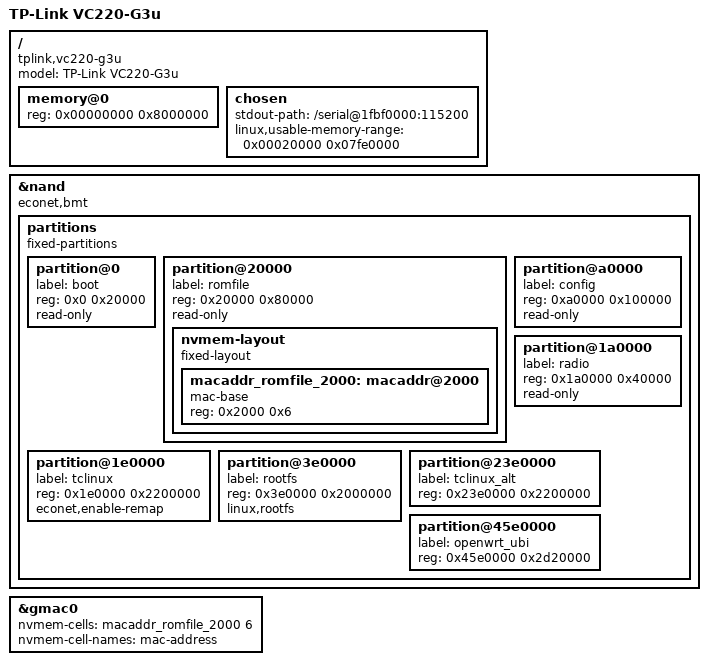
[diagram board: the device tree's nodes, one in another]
// SPDX-License-Identifier: (GPL-2.0-only OR BSD-2-Clause)
/dts-v1/;

#include "en751221.dtsi"

/ {
	model = "TP-Link VC220-G3u";
	compatible = "tplink,vc220-g3u", "econet,en751221";

	memory@0 {
		device_type = "memory";
		reg = <0x00000000 0x8000000>;
	};

	chosen {
		stdout-path = "/serial@1fbf0000:115200";
		linux,usable-memory-range = <0x00020000 0x07fe0000>;
	};
};

&nand {
	status = "okay";
	econet,bmt;

	partitions {
		compatible = "fixed-partitions";
		#address-cells = <1>;
		#size-cells = <1>;

		partition@0 {
			label = "boot";
			reg = <0x0 0x20000>;
			read-only;
		};
		partition@20000 {
			label = "romfile";
			reg = <0x20000 0x80000>;
			read-only;
			nvmem-layout {
				compatible = "fixed-layout";
				#address-cells = <1>;
				#size-cells = <1>;
				macaddr_romfile_2000: macaddr@2000 {
					compatible = "mac-base";
					reg = <0x2000 0x6>;
					#nvmem-cell-cells = <1>;
				};
			};
		};
		partition@a0000 {
			label = "config";
			reg = <0xa0000 0x100000>;
			read-only;
		};
		partition@1a0000 {
			label = "radio";
			reg = <0x1a0000 0x40000>;
			read-only;
		};
		partition@1e0000 {
			label = "tclinux";
			reg = <0x1e0000 0x2200000>;
			econet,enable-remap;
		};
		partition@3e0000 {
			label = "rootfs";
			reg = <0x3e0000 0x2000000>;
			linux,rootfs;
		};
		partition@23e0000 {
			label = "tclinux_alt";
			reg = <0x23e0000 0x2200000>;
		};
		partition@45e0000 {
			label = "openwrt_ubi"; /* "reserve_area" in log */
			reg = <0x45e0000 0x2d20000>;
		};
		/* After the last partition there is some spare space which might be used
		 * by BMT */
	};
};

&gmac0 {
	status = "okay";
	nvmem-cells = <&macaddr_romfile_2000 6>;
	nvmem-cell-names = "mac-address";
};
